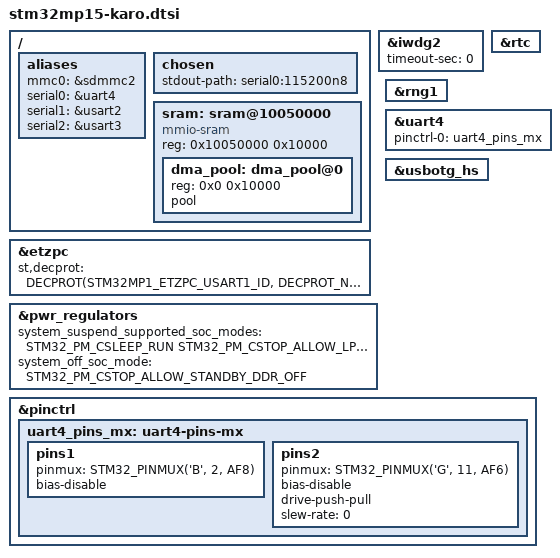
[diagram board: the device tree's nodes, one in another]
// SPDX-License-Identifier: (GPL-2.0 or BSD-3-Clause)
/*
 * Copyright (C) 2021 Lothar Waßmann <LW@KARO-electronics.de>
 */

#include "stm32mp15-ddr.dtsi"
#include <dt-bindings/clock/stm32mp1-clksrc.h>
#include <dt-bindings/power/stm32mp1-power.h>
#include <dt-bindings/soc/st,stm32-etzpc.h>

/ {
	aliases {
		mmc0 = &sdmmc2;
		serial0 = &uart4;
		serial1 = &usart2;
		serial2 = &usart3;
	};

	chosen {
		stdout-path = "serial0:115200n8";
	};

	sram: sram@10050000 {
		compatible = "mmio-sram";
		reg = <0x10050000 0x10000>;
		#address-cells = <1>;
		#size-cells = <1>;
		ranges = <0 0x10050000 0x10000>;

		dma_pool: dma_pool@0 {
			reg = <0x0 0x10000>;
			pool;
		};
	};
};

&etzpc {
	st,decprot = <
		DECPROT(STM32MP1_ETZPC_USART1_ID, DECPROT_NS_RW, DECPROT_UNLOCK)
		DECPROT(STM32MP1_ETZPC_SPI6_ID, DECPROT_NS_RW, DECPROT_UNLOCK)
		DECPROT(STM32MP1_ETZPC_I2C4_ID, DECPROT_NS_RW, DECPROT_UNLOCK)
		DECPROT(STM32MP1_ETZPC_I2C6_ID, DECPROT_NS_RW, DECPROT_UNLOCK)
		DECPROT(STM32MP1_ETZPC_RNG1_ID, DECPROT_NS_RW, DECPROT_UNLOCK)
		DECPROT(STM32MP1_ETZPC_HASH1_ID, DECPROT_NS_RW, DECPROT_UNLOCK)
		DECPROT(STM32MP1_ETZPC_CRYP1_ID, DECPROT_NS_RW, DECPROT_UNLOCK)
		DECPROT(STM32MP1_ETZPC_DDRCTRL_ID, DECPROT_NS_R_S_W, DECPROT_LOCK)
		DECPROT(STM32MP1_ETZPC_DDRPHYC_ID, DECPROT_NS_R_S_W, DECPROT_LOCK)
		DECPROT(STM32MP1_ETZPC_STGENC_ID, DECPROT_S_RW, DECPROT_LOCK)
		DECPROT(STM32MP1_ETZPC_BKPSRAM_ID, DECPROT_S_RW, DECPROT_LOCK)
		DECPROT(STM32MP1_ETZPC_IWDG1_ID, DECPROT_S_RW, DECPROT_LOCK)
	>;
};

&iwdg2 {
	timeout-sec = <0>;
	status = "okay";
};

&pwr_regulators {
	system_suspend_supported_soc_modes = <
		STM32_PM_CSLEEP_RUN
		STM32_PM_CSTOP_ALLOW_LP_STOP
		STM32_PM_CSTOP_ALLOW_STANDBY_DDR_SR
	>;
	system_off_soc_mode = <STM32_PM_CSTOP_ALLOW_STANDBY_DDR_OFF>;
	//vdd-supply = <&vdd>;
	//vdd_3v3_usbfs-supply = <&vdd_usb>;
};

&rng1 {
	status = "okay";
};

&rtc {
	status = "okay";
};

&uart4 {
	pinctrl-names = "default";
	pinctrl-0 = <&uart4_pins_mx>;
	status = "okay";
};

&usbotg_hs {
	status = "okay";
};

&pinctrl {
	uart4_pins_mx: uart4-pins-mx {
		pins1 {
			pinmux = <STM32_PINMUX('B', 2, AF8)>; /* UART4_RX */
			bias-disable;
		};

		pins2 {
			pinmux = <STM32_PINMUX('G', 11, AF6)>; /* UART4_TX */
			bias-disable;
			drive-push-pull;
			slew-rate = <0>;
		};
	};
};
